# RN8XXX_V2 register map
File version: 1.0
Registers are 32-bit, read-write, reset 0x0 unless marked. A register's access mark holds for its fields unless they carry their own. Offsets are from the block's base; [hi:lo] are bit positions; {n}, {i} and the like mark numbered series; 'fields as' and 'values as' point back to an identical list.

## KBI — key detection
Base 0x40028000
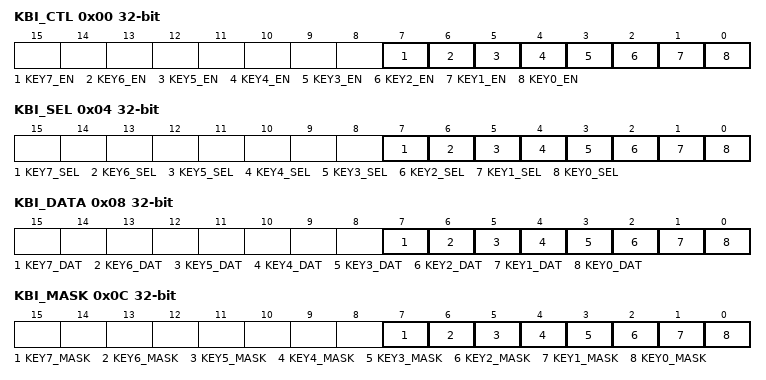
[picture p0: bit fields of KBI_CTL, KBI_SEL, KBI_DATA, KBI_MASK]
0x00 KBI_CTL — KBI control register.
  [all] fields
    0=disable (KEY detection disabled); 1=enable (KEY detection enabled)
  [7] KEY7_EN — KEY No.7 enable bits
  [6] KEY6_EN — KEY No.6 enable bits
  [5] KEY5_EN — KEY No.5 enable bits
  [4] KEY4_EN — KEY No.4 enable bits
  [3] KEY3_EN — KEY No.3 enable bits
  [2] KEY2_EN — KEY No.2 enable bits
  [1] KEY1_EN — KEY No.1 enable bits
  [0] KEY0_EN — KEY No.0 enable bits
0x04 KBI_SEL — KBI trigger mode selection
  [all] fields
    0=rising edge on KEY taken as an event; 1=falling edge on KEY taken as an event
  [7] KEY7_SEL — KEY No.7 trigger mode selection
  [6] KEY6_SEL — KEY No.6 trigger mode selection
  [5] KEY5_SEL — KEY No.5 trigger mode selection
  [4] KEY4_SEL — KEY No.4 trigger mode selection
  [3] KEY3_SEL — KEY No.3 trigger mode selection
  [2] KEY2_SEL — KEY No.2 trigger mode selection
  [1] KEY1_SEL — KEY No.1 trigger mode selection
  [0] KEY0_SEL — KEY No.0 trigger mode selection
0x08 KBI_DATA — KEY event
  [all] fields
    0=not_pressed (key has not yet been pressed); 1=pressed (key has been pressed)
  [7] KEY7_DAT write-1-clears — KEY No.7 trigger mode selection
  [6] KEY6_DAT write-1-clears — KEY No.6 trigger mode selection
  [5] KEY5_DAT write-1-clears — KEY No.5 trigger mode selection
  [4] KEY4_DAT write-1-clears — KEY No.4 trigger mode selection
  [3] KEY3_DAT write-1-clears — KEY No.3 trigger mode selection
  [2] KEY2_DAT write-1-clears — KEY No.2 trigger mode selection
  [1] KEY1_DAT write-1-clears — KEY No.1 trigger mode selection
  [0] KEY0_DAT write-1-clears — KEY No. 0 press status
0x0C KBI_MASK — interrupt mask
  [all] fields
    0=disable (do not generate interrupt on press event); 1=enable (generate interrupt on press event)
  [7] KEY7_MASK — KEY No.7 trigger mode selection
  [6] KEY6_MASK — KEY No.6 trigger mode selection
  [5] KEY5_MASK — KEY No.5 trigger mode selection
  [4] KEY4_MASK — KEY No.4 trigger mode selection
  [3] KEY3_MASK — KEY No.3 trigger mode selection
  [2] KEY2_MASK — KEY No.2 trigger mode selection
  [1] KEY1_MASK — KEY No.1 trigger mode selection
  [0] KEY0_MASK — KEY No.0 interrupt enable

## WDT — watchdog timer
Base 0x40030000
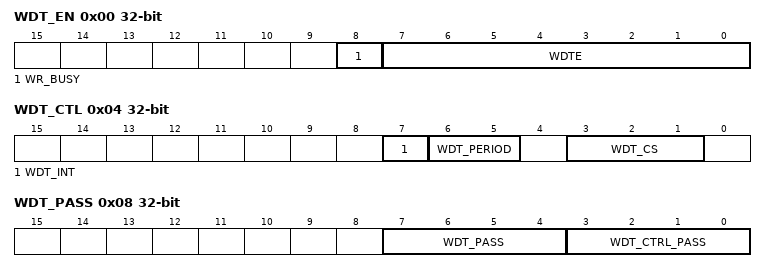
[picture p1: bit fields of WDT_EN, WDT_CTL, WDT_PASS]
0x00 WDT_EN — Watchdog enable register.
  [8] WR_BUSY ro — WDT busy
    0=no busy; 1=busy (WDT busy)
  [7:0] WDTE — WDT enable
    85=disable (WDT disabled (after power-on)); 170=enable (WDT enabled (after power-on)); 187=restart (clear WDT counter and restart WDT)
0x04 WDT_CTL — Watchdog control register
  [7] WDT_INT — WDT interrupt enable
  [6:5] WDT_PERIOD
  [3:1] WDT_CS — WDT counter overflow time config
    0=16ms; 1=32ms; 2=128ms; 3=512ms; 4=1s; 5=2s; 6=4s; 7=8s
0x08 WDT_PASS — Watchdog control register set access protection
  [7:4] WDT_PASS — WDT_PASS register set access protection
  [3:0] WDT_CTRL_PASS — WDT control register set access protection
0x14 WDT_HALT — Watchdog HALT mode register
  [15:0] WDT_HALT_EN — WDT HALT ,0x7e5a: WDT stop when CPU halt(halted by debugger), else WDT keeps running
0x18 WDT_STBY — Watchdog STANDBY mode register
  [15:0] WDT_STDBY_EN — WDT STANDBY ,0x7e5a: WDT stop when CPU standby(halted by debugger), else WDT keeps running

## simptc
Base 0x40060000
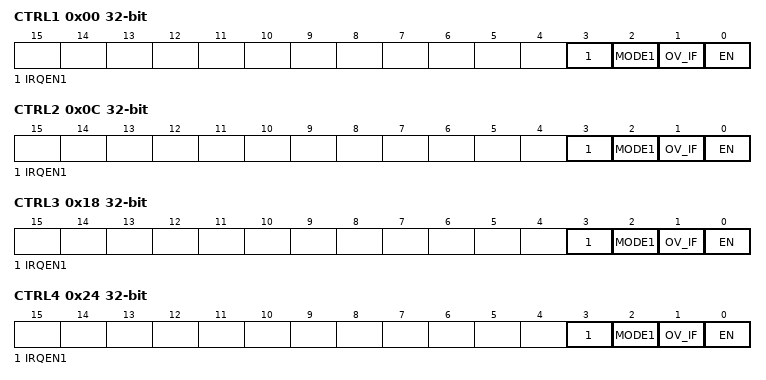
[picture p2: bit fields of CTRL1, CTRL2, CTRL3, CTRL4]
0x00 CTRL1 — SIMTC control register.1
  [3] IRQEN1 — interrupt enable
    0=disable (do not generate interrupt on overflow event); 1=enable (generate interrupt on overflow event)
  [2] MODE1 — one pulse mode selection
    0=enable (one pulse mode enabled(timer stop counting when overflow)); 1=disable (one pulse mode disabled(timer continue counting when overflow))
  [1] OV_IF write-1-clears — SIMTC overflow overflow interrupt flag
    0=no_pending (no overflow event found); 1=pending overflow event found
  [0] EN — SIMTC enable
    0=stop (SIMTC stop); 1=enable (SIMTC start)
0x04 LOAD1 — SIMTC target counter register.1
  [15:0] SIMPTC_TCNT — target counting value
0x08 VAL1 — SIMTC counter register.1
  [15:0] SIMPTC_CNT ro — current counting value
0x0C CTRL2 — SIMTC control register.2
  fields as CTRL1
0x10 LOAD2 — SIMTC target counter register.2
  [15:0] SIMPTC_TCNT — target counting value
0x14 VAL2 — SIMTC counter register.2
  [15:0] SIMPTC_CNT ro — current counting value
0x18 CTRL3 — SIMTC control register.3
  fields as CTRL1
0x1C LOAD3 — SIMTC target counter register.3
  [15:0] SIMPTC_TCNT — target counting value
0x20 VAL3 — SIMTC counter register.3
  [15:0] SIMPTC_CNT ro — current counting value
0x24 CTRL4 — SIMTC control register.4
  fields as CTRL1
0x28 LOAD4 — SIMTC target counter register.4
  [15:0] SIMPTC_TCNT — target counting value
0x2C VAL4 — SIMTC counter register.4
  [15:0] SIMPTC_CNT ro — current counting value

## d2f — Energy Digital Integrator frequency converter
Base 0x4005C000
0x00 HFconst3 — High frequency CF constant register.3
  [15:0] HFCONST — High frequency CF constant value
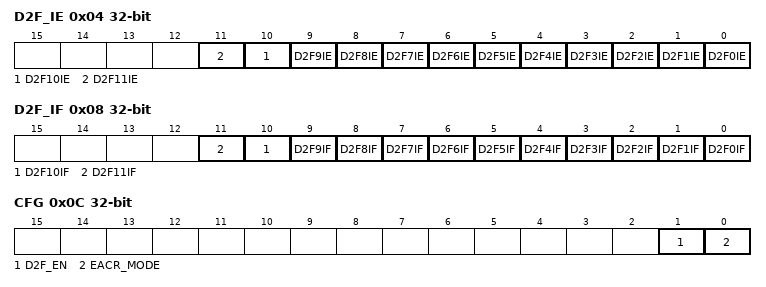
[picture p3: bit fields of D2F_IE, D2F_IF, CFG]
0x04 D2F_IE — Energy Digital Integrator interrupt enable register
  [all] fields
    0=disable (do not generate interrupt event); 1=enable (generate interrupt event)
  [n] D2F{n}IE (n=0..11) — D2F{n} interrupt enable
0x08 D2F_IF — Energy Digital Integrator interrupt flag register
  [all] fields
    0=no pending interrupt event; 1=pending interrupt event
  [n] D2F{n}IF write-1-clears (n=0..11) — D2F{n} interrupt
0x0C CFG — D2F config register
  [1] D2F_EN — D2F enable
    1=disable D2F; 0=enable D2F
  [0] EACR_MODE — energy accumulation mode
    0=read_clear (clear after read); 1=acr_mode (accumulation mode, not clear after read)
{0x10+4i} D2FP{i:02} (i=0..11) — D2FP power input register {i}
{0x40+4i} D2FE{i:02} (i=0..11) — D2FE energy input register {i}

## m2m — DMA memory access
Base 0x40068000
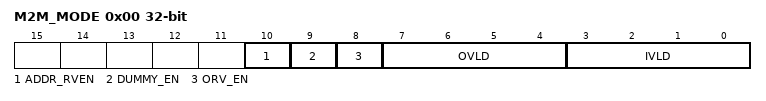
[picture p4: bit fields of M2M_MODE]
0x00 M2M_MODE
  [10] ADDR_RVEN — address order reverse enable
    0=disable address order reverse; 1=enable address order reverse
  [9] DUMMY_EN — dummy byte enable
    0=disable dummy byte; 1=enable dummy byte
  [8] ORV_EN — byte order reverse enable
    0=disable byte order reverse; 1=enable byte order reverse
  [7:4] OVLD — Output data valid
  [3:0] IVLD — input Data valid
0x04 M2M_CTL — M2M control register
  [0] M2M_EN — M2M enable
    0=disable; 1=enable
0x08 M2M_DUMMY
0x0C M2M_SADDR — M2M source address register
0x10 M2M_DADDR — M2M destination address register
0x14 M2M_ILEN — M2M length register
  [15:0] ILEN — M2M length
0x18 M2M_IE — M2M interrupt enable register
  [0] DONE_IE — M2M done interrupt enable
    0=disable (do not generate interrupt event); 1=enable (generate interrupt event)
0x1C M2M_IF — M2M interrupt flag register
  [0] DONE — M2M done interrupt event flag
    0=no pending interrupt event found; 1=pending interrupt event found
